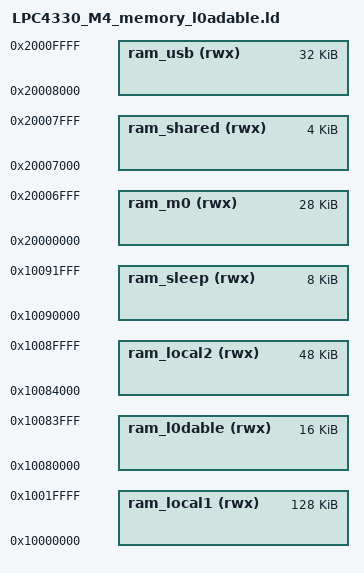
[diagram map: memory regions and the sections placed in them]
/*
 * Copyright 2012 Michael Ossmann <mike@ossmann.com>
 * Copyright 2012 Jared Boone <jared@sharebrained.com>
 * Copyright 2017 K. J. Temkin <k@ktemkin.com>
 * All rights reserved.
 *
 * Redistribution and use in source and binary forms, with or without
 * modification, are permitted provided that the following conditions are met:
 *
 * 1. Redistributions of source code must retain the above copyright notice,
 *    this list of conditions and the following disclaimer.
 * 2. Redistributions in binary form must reproduce the above copyright notice,
 *    this list of conditions and the following disclaimer in the documentation
 *    and/or other materials provided with the distribution.
 * 3. Neither the name of the copyright holder nor the names of its contributors
 *    may be used to endorse or promote products derived from this software
 *    without specific prior written permission.
 *
 *  THIS SOFTWARE IS PROVIDED BY THE COPYRIGHT HOLDERS AND CONTRIBUTORS "AS IS"
 *  AND ANY EXPRESS OR IMPLIED WARRANTIES, INCLUDING, BUT NOT LIMITED TO, THE
 *  IMPLIED WARRANTIES OF MERCHANTABILITY AND FITNESS FOR A PARTICULAR PURPOSE
 *  ARE DISCLAIMED. IN NO EVENT SHALL THE COPYRIGHT HOLDER OR CONTRIBUTORS BE
 *  LIABLE FOR ANY DIRECT, INDIRECT, INCIDENTAL, SPECIAL, EXEMPLARY, OR
 *  CONSEQUENTIAL DAMAGES (INCLUDING, BUT NOT LIMITED TO, PROCUREMENT OF
 *  SUBSTITUTE GOODS OR SERVICES; LOSS OF USE, DATA, OR PROFITS; OR BUSINESS
 *  INTERRUPTION) HOWEVER CAUSED AND ON ANY THEORY OF LIABILITY, WHETHER IN
 *  CONTRACT, STRICT LIABILITY, OR TORT (INCLUDING NEGLIGENCE OR OTHERWISE)
 *  ARISING IN ANY WAY OUT OF THE USE OF THIS SOFTWARE, EVEN IF ADVISED OF THE
 *  POSSIBILITY OF SUCH DAMAGE.
 */

MEMORY
{
	ram_local1 (rwx) : ORIGIN = 0x10000000, LENGTH = 128K
	ram_l0dable(rwx) : ORIGIN = 0x10080000, LENGTH = 16K
	ram_local2 (rwx) : ORIGIN = 0x10084000, LENGTH = 48K
	ram_sleep  (rwx) : ORIGIN = 0x10090000, LENGTH = 8K

	ram_m0     (rwx) : ORIGIN = 0x20000000, LENGTH = 28K
	ram_shared (rwx) : ORIGIN = 0x20007000, LENGTH =  4K
	ram_usb    (rwx) : ORIGIN = 0x20008000, LENGTH = 32K
}

usb_bulk_buffer = ORIGIN(ram_usb);
